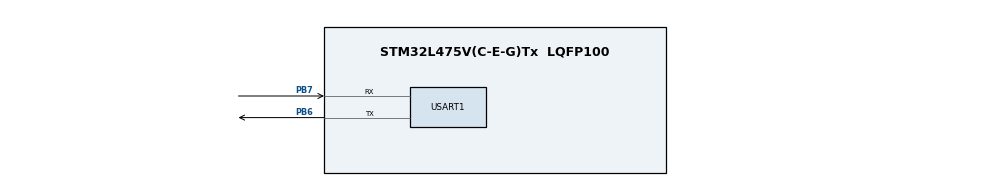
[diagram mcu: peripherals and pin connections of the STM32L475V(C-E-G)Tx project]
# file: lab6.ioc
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ADC1.Channel-1\#ChannelRegularConversion=ADC_CHANNEL_TEMPSENSOR
ADC1.ExternalTrigConv=ADC_EXTERNALTRIG_T1_TRGO
ADC1.NbrOfConversion=1
ADC1.NbrOfConversionFlag=1
ADC1.OffsetNumber-1\#ChannelRegularConversion=ADC_OFFSET_NONE
ADC1.Rank-1\#ChannelRegularConversion=1
ADC1.SamplingTime-1\#ChannelRegularConversion=ADC_SAMPLETIME_640CYCLES_5
ADC1.master=1
FREERTOS.BinarySemaphores01=adcSem,Dynamic,NULL,Depleted
FREERTOS.Tasks01=defaultTask,24,128,StartDefaultTask,Default,NULL,Dynamic,NULL,NULL;adcTask,24,512,StartAdcTask,Default,NULL,Dynamic,NULL,NULL
Mcu.Family=STM32L4
Mcu.Name=STM32L475V(C-E-G)Tx
Mcu.Package=LQFP100
NVIC.ADC1_2_IRQn=true\:5\:0\:true\:false\:true\:true\:true\:true\:true
NVIC.PriorityGroup=NVIC_PRIORITYGROUP_4
NVIC.TIM6_DAC_IRQn=true\:15\:0\:false\:false\:true\:false\:false\:true\:true
NVIC.TimeBase=TIM6_DAC_IRQn
NVIC.TimeBaseIP=TIM6
PA13\ (JTMS-SWDIO).Mode=Serial_Wire
PA13\ (JTMS-SWDIO).Signal=SYS_JTMS-SWDIO
PA14\ (JTCK-SWCLK).Mode=Serial_Wire
PA14\ (JTCK-SWCLK).Signal=SYS_JTCK-SWCLK
PB6.Mode=Asynchronous
PB6.Signal=USART1_TX
PB7.Mode=Asynchronous
PB7.Signal=USART1_RX
ProjectManager.HeapSize=0x200
ProjectManager.StackSize=0x400
ProjectManager.TargetToolchain=STM32CubeIDE
RCC.ADCFreq_Value=32000000
RCC.HSE_VALUE=8000000
RCC.HSI_VALUE=16000000
RCC.LSE_VALUE=32768
RCC.MSI_VALUE=4000000
RCC.PLLSAI1N=16
RCC.USBFreq_Value=32000000
RCC.VCOOutputFreq_Value=32000000
TIM1.Period=99
TIM1.Prescaler=3999
TIM1.TIM_MasterOutputTrigger=TIM_TRGO_UPDATE
USART1.VirtualMode-Asynchronous=VM_ASYNC
VP_ADC1_TempSens_Input.Mode=IN-TempSens
VP_FREERTOS_VS_CMSIS_V2.Mode=CMSIS_V2
VP_SYS_VS_tim6.Mode=TIM6
VP_TIM1_VS_ClockSourceINT.Mode=Internal
board=custom

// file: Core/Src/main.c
/* USER CODE BEGIN Header */
/**
  ******************************************************************************
  * @file           : main.c
  * @brief          : Main program body
  ******************************************************************************
  * @attention
  *
  * Copyright (c) 2026 STMicroelectronics.
  * All rights reserved.
  *
  * This software is licensed under terms that can be found in the LICENSE file
  * in the root directory of this software component.
  * If no LICENSE file comes with this software, it is provided AS-IS.
  *
  ******************************************************************************
  */
/* USER CODE END Header */
#include "main.h"
#include "cmsis_os.h"

/* USER CODE BEGIN Includes */
#include <stdio.h>
/* USER CODE END Includes */

ADC_HandleTypeDef hadc1;

TIM_HandleTypeDef htim1;

UART_HandleTypeDef huart1;

/* Definitions for defaultTask */
osThreadId_t defaultTaskHandle;
const osThreadAttr_t defaultTask_attributes = {
  .name = "defaultTask",
  .stack_size = 128 * 4,
  .priority = (osPriority_t) osPriorityNormal,
};
/* Definitions for adcTask */
osThreadId_t adcTaskHandle;
const osThreadAttr_t adcTask_attributes = {
  .name = "adcTask",
  .stack_size = 512 * 4,
  .priority = (osPriority_t) osPriorityNormal,
};
/* Definitions for adcSem */
osSemaphoreId_t adcSemHandle;
const osSemaphoreAttr_t adcSem_attributes = {
  .name = "adcSem"
};

void SystemClock_Config(void);
static void MX_GPIO_Init(void);
static void MX_ADC1_Init(void);
static void MX_TIM1_Init(void);
static void MX_USART1_UART_Init(void);
void StartDefaultTask(void *argument);
void StartAdcTask(void *argument);

int main(void)
{

  /* MCU Configuration--------------------------------------------------------*/

  /* Reset of all peripherals, Initializes the Flash interface and the Systick. */
  HAL_Init();

  /* Configure the system clock */
  SystemClock_Config();

  /* Initialize all configured peripherals */
  MX_GPIO_Init();
  MX_ADC1_Init();
  MX_TIM1_Init();
  MX_USART1_UART_Init();

  /* Init scheduler */
  osKernelInitialize();

  /* Create the semaphores(s) */
  /* creation of adcSem */
  adcSemHandle = osSemaphoreNew(1, 0, &adcSem_attributes);

  /* Create the thread(s) */
  /* creation of defaultTask */
  defaultTaskHandle = osThreadNew(StartDefaultTask, NULL, &defaultTask_attributes);

  /* creation of adcTask */
  adcTaskHandle = osThreadNew(StartAdcTask, NULL, &adcTask_attributes);

  /* Start scheduler */
  osKernelStart();

  /* We should never get here as control is now taken by the scheduler */

  /* Infinite loop */
  while (1)
  {

  }
}

void SystemClock_Config(void)
{
  RCC_OscInitTypeDef RCC_OscInitStruct = {0};
  RCC_ClkInitTypeDef RCC_ClkInitStruct = {0};

  /** Configure the main internal regulator output voltage
  */
  if (HAL_PWREx_ControlVoltageScaling(PWR_REGULATOR_VOLTAGE_SCALE1) != HAL_OK)
  {
    Error_Handler();
  }

  /** Initializes the RCC Oscillators according to the specified parameters
  * in the RCC_OscInitTypeDef structure.
  */
  RCC_OscInitStruct.OscillatorType = RCC_OSCILLATORTYPE_MSI;
  RCC_OscInitStruct.MSIState = RCC_MSI_ON;
  RCC_OscInitStruct.MSICalibrationValue = 0;
  RCC_OscInitStruct.MSIClockRange = RCC_MSIRANGE_6;
  RCC_OscInitStruct.PLL.PLLState = RCC_PLL_NONE;
  if (HAL_RCC_OscConfig(&RCC_OscInitStruct) != HAL_OK)
  {
    Error_Handler();
  }

  /** Initializes the CPU, AHB and APB buses clocks
  */
  RCC_ClkInitStruct.ClockType = RCC_CLOCKTYPE_HCLK|RCC_CLOCKTYPE_SYSCLK
                              |RCC_CLOCKTYPE_PCLK1|RCC_CLOCKTYPE_PCLK2;
  RCC_ClkInitStruct.SYSCLKSource = RCC_SYSCLKSOURCE_MSI;
  RCC_ClkInitStruct.AHBCLKDivider = RCC_SYSCLK_DIV1;
  RCC_ClkInitStruct.APB1CLKDivider = RCC_HCLK_DIV1;
  RCC_ClkInitStruct.APB2CLKDivider = RCC_HCLK_DIV1;

  if (HAL_RCC_ClockConfig(&RCC_ClkInitStruct, FLASH_LATENCY_0) != HAL_OK)
  {
    Error_Handler();
  }
}

static void MX_ADC1_Init(void)
{

  ADC_MultiModeTypeDef multimode = {0};
  ADC_ChannelConfTypeDef sConfig = {0};

  /** Common config
  */
  hadc1.Instance = ADC1;
  hadc1.Init.ClockPrescaler = ADC_CLOCK_ASYNC_DIV1;
  hadc1.Init.Resolution = ADC_RESOLUTION_12B;
  hadc1.Init.DataAlign = ADC_DATAALIGN_RIGHT;
  hadc1.Init.ScanConvMode = ADC_SCAN_DISABLE;
  hadc1.Init.EOCSelection = ADC_EOC_SINGLE_CONV;
  hadc1.Init.LowPowerAutoWait = DISABLE;
  hadc1.Init.ContinuousConvMode = DISABLE;
  hadc1.Init.NbrOfConversion = 1;
  hadc1.Init.DiscontinuousConvMode = DISABLE;
  hadc1.Init.ExternalTrigConv = ADC_EXTERNALTRIG_T1_TRGO;
  hadc1.Init.ExternalTrigConvEdge = ADC_EXTERNALTRIGCONVEDGE_RISING;
  hadc1.Init.DMAContinuousRequests = DISABLE;
  hadc1.Init.Overrun = ADC_OVR_DATA_PRESERVED;
  hadc1.Init.OversamplingMode = DISABLE;
  if (HAL_ADC_Init(&hadc1) != HAL_OK)
  {
    Error_Handler();
  }

  /** Configure the ADC multi-mode
  */
  multimode.Mode = ADC_MODE_INDEPENDENT;
  if (HAL_ADCEx_MultiModeConfigChannel(&hadc1, &multimode) != HAL_OK)
  {
    Error_Handler();
  }

  /** Configure Regular Channel
  */
  sConfig.Channel = ADC_CHANNEL_TEMPSENSOR;
  sConfig.Rank = ADC_REGULAR_RANK_1;
  sConfig.SamplingTime = ADC_SAMPLETIME_640CYCLES_5;
  sConfig.SingleDiff = ADC_SINGLE_ENDED;
  sConfig.OffsetNumber = ADC_OFFSET_NONE;
  sConfig.Offset = 0;
  if (HAL_ADC_ConfigChannel(&hadc1, &sConfig) != HAL_OK)
  {
    Error_Handler();
  }

}

static void MX_TIM1_Init(void)
{

  TIM_ClockConfigTypeDef sClockSourceConfig = {0};
  TIM_MasterConfigTypeDef sMasterConfig = {0};

  htim1.Instance = TIM1;
  htim1.Init.Prescaler = 3999;
  htim1.Init.CounterMode = TIM_COUNTERMODE_UP;
  htim1.Init.Period = 99;
  htim1.Init.ClockDivision = TIM_CLOCKDIVISION_DIV1;
  htim1.Init.RepetitionCounter = 0;
  htim1.Init.AutoReloadPreload = TIM_AUTORELOAD_PRELOAD_DISABLE;
  if (HAL_TIM_Base_Init(&htim1) != HAL_OK)
  {
    Error_Handler();
  }
  sClockSourceConfig.ClockSource = TIM_CLOCKSOURCE_INTERNAL;
  if (HAL_TIM_ConfigClockSource(&htim1, &sClockSourceConfig) != HAL_OK)
  {
    Error_Handler();
  }
  sMasterConfig.MasterOutputTrigger = TIM_TRGO_UPDATE;
  sMasterConfig.MasterOutputTrigger2 = TIM_TRGO2_RESET;
  sMasterConfig.MasterSlaveMode = TIM_MASTERSLAVEMODE_DISABLE;
  if (HAL_TIMEx_MasterConfigSynchronization(&htim1, &sMasterConfig) != HAL_OK)
  {
    Error_Handler();
  }

}

static void MX_USART1_UART_Init(void)
{

  huart1.Instance = USART1;
  huart1.Init.BaudRate = 115200;
  huart1.Init.WordLength = UART_WORDLENGTH_8B;
  huart1.Init.StopBits = UART_STOPBITS_1;
  huart1.Init.Parity = UART_PARITY_NONE;
  huart1.Init.Mode = UART_MODE_TX_RX;
  huart1.Init.HwFlowCtl = UART_HWCONTROL_NONE;
  huart1.Init.OverSampling = UART_OVERSAMPLING_16;
  huart1.Init.OneBitSampling = UART_ONE_BIT_SAMPLE_DISABLE;
  huart1.AdvancedInit.AdvFeatureInit = UART_ADVFEATURE_NO_INIT;
  if (HAL_UART_Init(&huart1) != HAL_OK)
  {
    Error_Handler();
  }

}

static void MX_GPIO_Init(void)
{

  /* GPIO Ports Clock Enable */
  __HAL_RCC_GPIOA_CLK_ENABLE();
  __HAL_RCC_GPIOB_CLK_ENABLE();

}

/* USER CODE BEGIN 4 */
void HAL_ADC_ConvCpltCallback(ADC_HandleTypeDef *hadc)
{
    if (hadc->Instance == ADC1)
    {
        osSemaphoreRelease(adcSemHandle);
    }
}
/* USER CODE END 4 */

void StartDefaultTask(void *argument)
{
  for(;;)
  {
    osDelay(1);
  }
}

void StartAdcTask(void *argument)
{
  /* USER CODE BEGIN StartAdcTask */

  char msg[64];
  if (HAL_ADCEx_Calibration_Start(&hadc1, ADC_SINGLE_ENDED) != HAL_OK)
  {
      Error_Handler();
  }
  if (HAL_ADC_Start_IT(&hadc1) != HAL_OK)
  {
    Error_Handler();
  }

  if (HAL_TIM_Base_Start(&htim1) != HAL_OK)
  {
    Error_Handler();
  }

  for (;;)
  {
    if (osSemaphoreAcquire(adcSemHandle, osWaitForever) == osOK)
    {
    	uint32_t adcValue = HAL_ADC_GetValue(&hadc1);

    	int32_t temperature = __HAL_ADC_CALC_TEMPERATURE(
    	    3300,
    	    adcValue,
    	    ADC_RESOLUTION_12B
    	);

    	int len = snprintf(msg, sizeof(msg),
    	                   "ADC: %lu, Temp: %ld C\r\n",
    	                   (unsigned long)adcValue,
    	                   (long)temperature);

      if (len > 0 && len < (int)sizeof(msg))
      {
        HAL_UART_Transmit(&huart1, (uint8_t *)msg, len, 100);
      }
    }
  }

  /* USER CODE END StartAdcTask */
}

void HAL_TIM_PeriodElapsedCallback(TIM_HandleTypeDef *htim)
{
  if (htim->Instance == TIM6)
  {
    HAL_IncTick();
  }
}

void Error_Handler(void)
{
  __disable_irq();
  while (1)
  {
  }
}
